# SIM3L164_C register map
File version: 1
CPU: 
Registers are 32-bit, read-write, reset 0x0 unless marked. A register's access mark holds for its fields unless they carry their own. Offsets are from the block's base; [hi:lo] are bit positions.

## ENCDEC_0
Base 0x4004F000
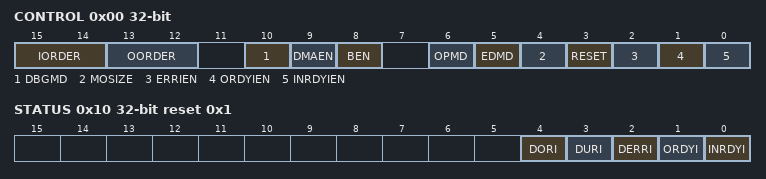
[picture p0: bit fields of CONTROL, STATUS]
0x00 CONTROL — Module Control
  [15:14] IORDER — Input Order Mode.
    0=NO_CHANGE (Data written to DATAIN is processed in the order written (input: B3 B2 B1 B0, output: B3 B2 B1 B0).); 1=HALF_WORD (The module flips the DATAIN input data in half-words (input: B2 B3 B0 B1, output: B3 B2 B1 B0).); 2=WORD (The module flips the DATAIN input data in words (input: B0 B1 B2 B3, output: B3 B2 B1 B0).); 3=LOWER_THREE_BYTES (The module flips the lower three bytes of the DATAIN input data (input: B3 B0 B1 B2, output: B3 B2 B1 B0).)
  [13:12] OORDER — Output Order Mode.
    0=NO_CHANGE (The module outputs data to DATAOUT in the same order as it was processed (input: B3 B2 B1 B0, output: B3 B2 B1 B0).); 1=HALF_WORD (The module flips the data in half-words before outputting to DATAOUT (input: B3 B2 B1 B0, output: B2 B3 B0 B1).); 2=WORD (The module flips the data in words before outputting to DATAOUT (input: B3 B2 B1 B0, output: B0 B1 B2 B3).); 3=LOWER_THREE_BYTES (The module flips the lower three bytes before outputting to DATAOUT (input: B3 B2 B1 B0, output: B3 B0 B1 B2).)
  [10] DBGMD — Debug Mode.
    0=RUN (The ENCDEC module will continue to operate while the core is halted in debug mode.); 1=HALT (A debug breakpoint will cause the ENCDEC module to halt.)
  [9] DMAEN — DMA Mode Enable.
    0=DISABLED (Disable DMA mode.); 1=ENABLED (Enable DMA mode.)
  [8] BEN — Bypass Encoder/Decoder Operation Enable.
    0=DISABLED (Do not bypass ENCDEC operations.); 1=ENABLED (Bypass ENCDEC operations.)
  [6] OPMD — Operation Mode.
    0=MANCHESTER (The operation selected by EDMD uses Manchester mode.); 1=3OUTOF6 (The operation selected by EDMD uses Three-out-of-Six mode.)
  [5] EDMD — Encode Decode Mode.
    0=DECODE (Decode data written to DATAIN.); 1=ENCODE (Encode data written to DATAIN.)
  [4] MOSIZE — Manchester Output Size.
    0=SMALL (Manchester encode operations generate a half-word output, and decode operations generate a byte output.); 1=LARGE (Manchester encode operations generate a word output, and decode operations generate a half-word output.)
  [3] RESET wo — Module Reset.
    1=ACTIVE (Reset the module.)
  [2] ERRIEN — Error Interrupt Enable.
    0=DISABLED (Disable the error interrupt.); 1=ENABLED (Enable the error interrupt.)
  [1] ORDYIEN — Output Ready Interrupt Enable.
    0=DISABLED (Disable the output ready interrupt.); 1=ENABLED (Enable the output ready interrupt.)
  [0] INRDYIEN — Input Ready Interrupt Enable.
    0=DISABLED (Disable the input ready interrupt.); 1=ENABLED (Enable the input ready interrupt.)
0x10 STATUS reset 0x1 — Module Status
  [4] DORI — Data Overrun Interrupt Flag.
    0=NOT_SET (No input data FIFO overrun.); 1=SET (An input data FIFO overrun has occurred.)
  [3] DURI — Data Underrun Interrupt Flag.
    0=NOT_SET (No output data FIFO underrun.); 1=SET (An output data FIFO underrun has occurred.)
  [2] DERRI — Data Error Interrupt Flag.
    0=NOT_SET; 1=SET
  [1] ORDYI ro — Output Ready Interrupt Flag.
    0=NOT_SET (The output data is not ready.); 1=SET (The output data is ready to be read by firmware.)
  [0] INRDYI ro — Input Ready Interrupt Flag.
    0=NOT_SET (The input FIFO is not ready for new data.); 1=SET (Firmware can write new input data to DATAIN.)
0x20 DATAIN read-has-side-effects — Data Input
  [31:0] DATAIN — Data Input.
0x30 DATAOUT read-has-side-effects — Data Output
  [31:0] DATAOUT — Data Output.
0x40 DATAOUTC reset 0xFFFFFFFF read-has-side-effects — Data Output Complement
  [31:0] DATAOUTC ro — Data Output Complement.

## LPOSC_0
Base 0x40041000
0x00 OSCVAL reset 0x8 — Low Power Oscillator Output Value
  [3:0] OSCVAL ro — Low Power Oscillator Output Value.
